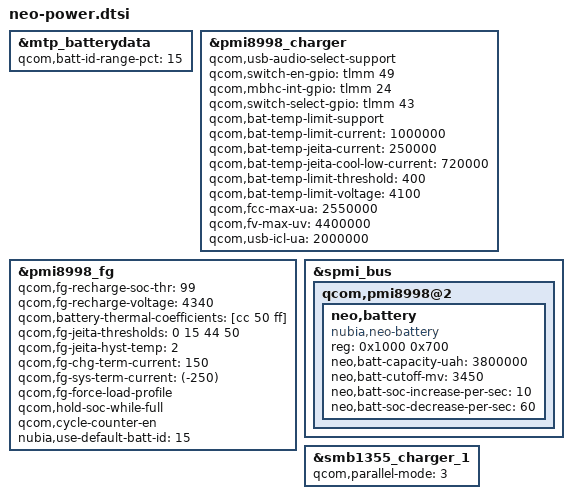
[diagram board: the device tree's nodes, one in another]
&mtp_batterydata {
	qcom,batt-id-range-pct = <15>;
	#include "fg-gen3-batterydata-atl-3800mah.dtsi"
};

&pmi8998_charger {
	qcom,usb-audio-select-support;
	qcom,switch-en-gpio = <&tlmm 49 0>;
	qcom,mbhc-int-gpio = <&tlmm 24 0>;
	qcom,switch-select-gpio = <&tlmm 43 0>;

	qcom,bat-temp-limit-support;
	qcom,bat-temp-limit-current = <1000000>;
	qcom,bat-temp-jeita-current = <250000>;
	qcom,bat-temp-jeita-cool-low-current = <720000>;
	qcom,bat-temp-limit-threshold = <400>;
	qcom,bat-temp-limit-voltage = <4100>;
	//qcom,step-soc-thresholds = <60 70 80 90>;
	//qcom,step-current-deltas = <400000 400000 0 0 0>;

	qcom,fcc-max-ua = <2550000>;
	qcom,fv-max-uv = <4400000>;
	qcom,usb-icl-ua = <2000000>;
};

&pmi8998_fg {
	qcom,fg-recharge-soc-thr = <99>;
	qcom,fg-recharge-voltage = <4340>;
	qcom,battery-thermal-coefficients = [cc 50 ff];
	qcom,fg-jeita-thresholds = <0 15 44 50>;
	qcom,fg-jeita-hyst-temp = <2>;
	qcom,fg-chg-term-current = <150>;
	qcom,fg-sys-term-current = <(-250)>;
	qcom,fg-force-load-profile;
	qcom,hold-soc-while-full;
	qcom,cycle-counter-en;
	nubia,use-default-batt-id = <15>;
};

&spmi_bus {
	qcom,pmi8998@2 {
		neo,battery {
			compatible = "nubia,neo-battery";
			#address-cells = <1>;
			#size-cells = <1>;
			reg = <0x1000 0x700>;
			neo,batt-capacity-uah = <3800000>;
			neo,batt-cutoff-mv = <3450>;
			neo,batt-soc-increase-per-sec = <10>;
			neo,batt-soc-decrease-per-sec = <60>;
		};
	};
};

&smb1355_charger_1 {
	qcom,parallel-mode = <3>;
};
